# R40 register map
Vendor: Allwinner; Series: R40; File version: 0.1
CPU: CA7 0, little endian, MPU, FPU, double-precision FPU, 0 interrupt priority bits
Registers are 32-bit, read-write, reset 0x0 unless marked. A register's access mark holds for its fields unless they carry their own. Offsets are from the block's base; [hi:lo] are bit positions; lines under a group give offsets from that group; {n}, {i} and the like mark numbered series; 'fields as' and 'values as' point back to an identical list.

## GMAC
Base 0x01C50000
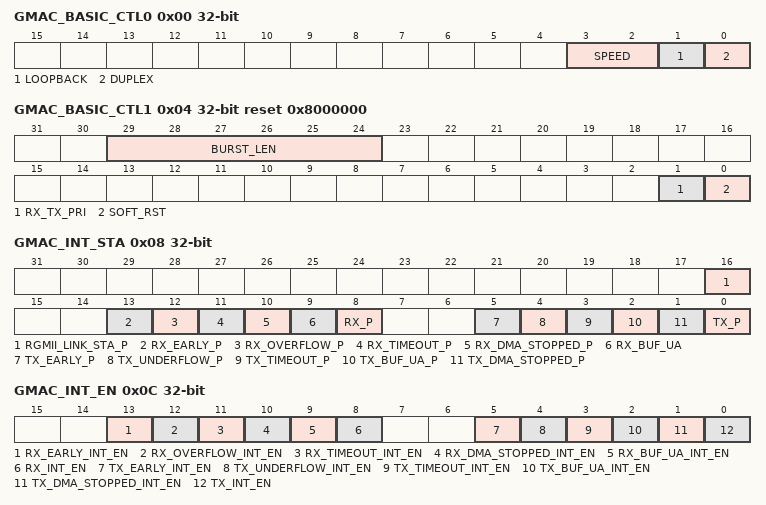
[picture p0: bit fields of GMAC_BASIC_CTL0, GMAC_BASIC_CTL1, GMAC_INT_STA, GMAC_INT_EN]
0x00 GMAC_BASIC_CTL0 — GMAC Basic Control Register0
  [3:2] SPEED — 00: 1000Mbps 01: Reserved 10: 10Mbps 11: 100Mbps
    0=_1000Mbps; 2=_10Mbps; 3=_100Mbps
  [1] LOOPBACK — 0: Disable 1: Enable
    0=Disable; 1=Enable
  [0] DUPLEX — 0: Half-duplex 1: Full-duplex
    0=half_duplex; 1=full_duplex
0x04 GMAC_BASIC_CTL1 reset 0x8000000 — GMAC Basic Control Register1
  [29:24] BURST_LEN — The burst length of RX and TX DMA transfer.
  [1] RX_TX_PRI — RX TX DMA priority 0: same priority 1: RX priority over TX
    0=same priority; 1=RX (RX priority over TX)
  [0] SOFT_RST — Soft Reset all Registers and Logic 0: No valid 1: Reset Note: All clock inputs must be valid before soft rest. This bit is cleared internally when the reset operation is completed fully. Before write any register, this bit should read a 0.
    0=No_valid; 1=Reset Note: All clock inputs must be valid before soft rest. This bit is cleared internally when the reset operation is completed fully. Before write any register, this bit should read a 0.
0x08 GMAC_INT_STA — GMAC Interrupt Status Register
  [16] RGMII_LINK_STA_P write-1-clears — RMII Link Status Changed Interrupt Pending 0: No Pending 1: Pending Note: Write `1` to clear
    0=No_Pending; 1=Pending Note: Write `1` to clear
  [13] RX_EARLY_P write-1-clears — RX DMA Filled First data Buffer of the Receive Frame Interrupt Pending 0: No Pending 1: Pending Note: Write `1` to clear
    0=No_Pending; 1=Pending Note: Write `1` to clear
  [12] RX_OVERFLOW_P write-1-clears — RX FIFO Overflow Error Interrupt Pending 0: No Pending 1: Pending Note: Write `1` to clear
    0=No_Pending; 1=Pending Note: Write `1` to clear
  [11] RX_TIMEOUT_P write-1-clears — RX Timeout Interrupt Pending 0: No Pending 1: Pending Note: Write `1` to clear .When this bit asserted, the length of receive frame is greater than 2048 bytes(10240 when JUMBO_FRM_EN is set)
    0=No_Pending; 1=Pending Note: Write `1` to clear .When this bit asserted, the length of receive frame is greater than 2048 bytes(10240 when JUMBO_FRM_EN is set)
  [10] RX_DMA_STOPPED_P write-1-clears — When this bit asserted, the RX DMA FSM is stopped.
  [9] RX_BUF_UA write-1-clears — _P RX Buffer UA Interrupt Pending 0: No Pending 1: Pending Note: Write `1` to clear .When this asserted, the RX DMA can`t acquire next RX descriptor and RX DMA FSM is suspended. The ownership of next RX descriptor should be changed to RX DMA. The RX DMA FSM will resume when write to DMA_RX_START bit or next receive frame is coming.
    0=No_Pending; 1=Pending Note: Write `1` to clear .When this asserted, the RX DMA can`t acquire next RX descriptor and RX DMA FSM is suspended. The ownership of next RX descriptor should be changed to RX DMA. The RX DMA FSM will resume when write to DMA_RX_START bit or next receive frame is coming.
  [8] RX_P write-1-clears — Frame RX Completed Interrupt Pending 0: No Pending 1: Pending Note: Write `1` to clear. When this bit is asserted, a frame reception is completed. The RX DMA FSM remains in the running state.
    0=No_Pending; 1=Pending Note: Write `1` to clear. When this bit is asserted, a frame reception is completed. The RX DMA FSM remains in the running state.
  [5] TX_EARLY_P write-1-clears — Frame is transmitted to FIFO totally Interrupt Pending 0: No Pending 1: Pending Note: Write `1` to clear.
    0=No_Pending; 1=Pending Note: Write `1` to clear
  [4] TX_UNDERFLOW_P write-1-clears — TX FIFO Underflow Interrupt Pending 0: No Pending 1: Pending Note: Write `1` to clear
    0=No_Pending; 1=Pending Note: Write `1` to clear
  [3] TX_TIMEOUT_P write-1-clears — Transmitter Timeout Interrupt Pending 0: No Pending 1: Pending Note: Write `1` to clear
    0=No_Pending; 1=Pending Note: Write `1` to clear
  [2] TX_BUF_UA_P write-1-clears — TX Buffer UA Interrupt Pending 0: No Pending 1: Pending When this asserted, the TX DMA can not acquire next TX descriptor and TX DMA FSM is suspended. The ownership of next TX descriptor should be changed to TX DMA. The TX DMA FSM will resume when write to DMA_TX_START bit.
    0=No_Pending; 1=Pending When this asserted, the TX DMA can not acquire next TX descriptor and TX DMA FSM is suspended. The ownership of next TX descriptor should be changed to TX DMA. The TX DMA FSM will resume when write to DMA_TX_START bit.
  [1] TX_DMA_STOPPED_P write-1-clears — Transmission DMA Stopped Interrupt Pending 0: No Pending 1: Pending Note: Write `1` to clear
    0=No_Pending; 1=Pending Note: Write `1` to clear
  [0] TX_P write-1-clears — Frame Transmission Interrupt Pending 0: No Pending 1: Pending Note: Write `1` to clear
    0=No_Pending; 1=Pending Note: Write `1` to clear
0x0C GMAC_INT_EN — GMAC Interrupt Enable Register
  [all] fields
    0=Disable; 1=Enable
  [13] RX_EARLY_INT_EN — Early Receive Interrupt 0: Disable 1: Enable
  [12] RX_OVERFLOW_INT_EN — Receive Overflow Interrupt 0: Disable 1: Enable
  [11] RX_TIMEOUT_INT_EN — Receive Timeout Interrupt 0: Disable 1: Enable
  [10] RX_DMA_STOPPED_INT_EN — Receive DMA FSM Stopped Interrupt 0: Disable 1: Enable
  [9] RX_BUF_UA_INT_EN — Receive Buffer Unavailable Interrupt 0: Disable 1: Enable
  [8] RX_INT_EN — Receive interrupt 0: Disable 1: Enable
  [5] TX_EARLY_INT_EN — Early Transmit Interrupt 0: Disable 1: Enable
  [4] TX_UNDERFLOW_INT_EN — Transmit Underflow Interrupt 0: Disable 1: Enable
  [3] TX_TIMEOUT_INT_EN — Transmit Timeout Interrupt 0: Disable 1: Enable
  [2] TX_BUF_UA_INT_EN — Transmit Buffer Available Interrupt 0: Disable 1: Enable
  [1] TX_DMA_STOPPED_INT_EN — Transmit DMA FSM Stopped Interrupt 0: Disable 1: Enable
  [0] TX_INT_EN — Transmit interrupt 0: Disable 1: Enable
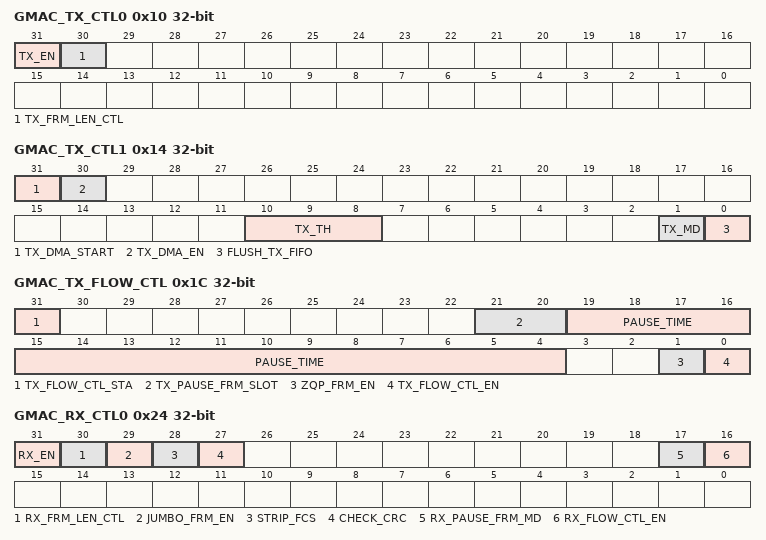
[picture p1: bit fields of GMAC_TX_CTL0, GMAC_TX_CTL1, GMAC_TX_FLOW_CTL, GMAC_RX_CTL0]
0x10 GMAC_TX_CTL0 — GMAC Transmit Control Register0
  [31] TX_EN — Enable transmitter. 0: Disable 1: Enable Note: When disable, transmit will continue until current transmit finish.
    0=Disable; 1=Enable Note: When disable, transmit will continue until current transmit finish
  [30] TX_FRM_LEN_CTL — Frame Transmit Length Control 0: Up to 2,048 bytes (JUMBO_FRM_EN==0) Up to 10,240 bytes (JUMBO_FRM_EN==1) 1: Up to 16,384 bytes Note: any bytes after that is cut off
    0=Up_to_2_comma_048 (Up to 2,048 bytes (JUMBO_FRM_EN==0) Up to 10,240 bytes (JUMBO_FRM_EN==1)); 1=Up_to_16_comma_384 (Up to 16,384 bytes Note: any bytes after that is cut off)
0x14 GMAC_TX_CTL1 — GMAC Transmit Control Register1
  [31] TX_DMA_START — Transmit DMA FSM Start 0: No valid 1: Start Note: This cleared internally and always read a 0
    0=No_valid; 1=Start Note: This cleared internally and always read a 0
  [30] TX_DMA_EN — 0: Stop TX DMA after the completion of current frame transmission. 1: Start and run TX DMA.
    0=Stop TX DMA after the completion of current frame transmission; 1=Start and run TX DMA
  [10:8] TX_TH — The threshold value of TX DMA FIFO. When TX_MD is 0, transmission starts when the size of frame in TX DMA FIFO is greater than the threshold. In addition, full frames with a length less than the threshold are transferred automatically. 000: 64 001: 128 010: 192 011: 256 Others: Reserved
    0=_64; 1=_128; 2=_192; 3=_256
  [1] TX_MD — Transmission Mode 0: TX start after TX DMA FIFO bytes is greater than TX_TH 1: TX start after TX DMA FIFO located a full frame
    0=TX start after TX DMA FIFO bytes is greater than TX_TH; 1=TX start after TX DMA FIFO located a full frame
  [0] FLUSH_TX_FIFO — Flush the data in the TX FIFO. 0: Enable 1: Disable
    0=Enable; 1=Disable
0x1C GMAC_TX_FLOW_CTL — GMAC Transmit Flow Control Register
  [31] TX_FLOW_CTL_STA — This bit indicates a pause frame transmission is in progress. When the configuration of flow control is ready, set this bit to transmit a pause frame in full-duplex mode or activate the backpressure function. After completion of transmission, this bit will be cleared automatically. Before write register TX_FLOW_CTRL, this bit must be read as 0.
  [21:20] TX_PAUSE_FRM_SLOT — The threshold of the pause timer at which the input flow control signal is checked for automatic retransmission of pause frame. The threshold values should be always less than the PAUSE_TIME
  [19:4] PAUSE_TIME — The pause time field in the transmitted control frame.
  [1] ZQP_FRM_EN — 0: Disable 1: Enable When set, enable the functionality to generate Zero-Quanta Pause control frame.
    0=Disable; 1=Enable When set, enable the functionality to generate Zero-Quanta Pause control frame
  [0] TX_FLOW_CTL_EN — TX Flow Control Enable 0: Disable 1: Enable When set, enable flow control operation to transmit pause frames in full-duplex mode, or enable the back-pressure operation in half-duplex mode.
    0=Disable; 1=Enable When set, enable flow control operation to transmit pause frames in full-duplex mode, or enable the back-pressure operation in half-duplex mode
0x20 GMAC_TX_DMA_LIST
  [31:0] TX_DESC_LIST — The base address of transmit descriptor list. It must be 32-bit aligned.
0x24 GMAC_RX_CTL0 — GMAC Receive Control Register0
  [31] RX_EN — Enable receiver 0: Disable receiver after current reception 1: Enable
    0=Disable receiver after current reception; 1=Enable
  [30] RX_FRM_LEN_CTL — Frame Receive Length Control 0: Up to 2,048 bytes (JUMBO_FRM_EN==0) Up to 10,240 bytes (JUMBO_FRM_EN==1) 1: Up to 16,384 bytes Note: any bytes after that is cut off
    values as GMAC_TX_CTL0.TX_FRM_LEN_CTL
  [29] JUMBO_FRM_EN — Jumbo Frame Enable 0: Disable 1: Enable Jumbo frames of 9,018 bytes without reporting a giant
    0=Disable; 1=Enable Jumbo frames of 9,018 bytes without reporting a giant
  [28] STRIP_FCS — When set, strip the Pad/FCS field on received frames only when the length`s field value is less than or equal to 1,500 bytes.
  [27] CHECK_CRC — Check CRC anable 0: Disable 1: Calculate CRC and check the IPv4 Header Checksum.
    0=Disable; 1=Calculate CRC and check the IPv4 Header Checksum
  [17] RX_PAUSE_FRM_MD — 0: Only detect multicast pause frame specified in the 802.3x standard. 1: In addition to detect multicast pause frame specified in the 802.3x standard, also detect unicast pause frame with address specified in MAC Address 0 High Register and MAC address 0 Low Register.
    0=Only detect multicast pause frame specified in the 802.3x standard; 1=In (In addition to detect multicast pause frame specified in the 802.3x standard, also detect unicast pause frame with address specified in MAC Address 0 High Register and MAC address 0 Low Register.)
  [16] RX_FLOW_CTL_EN — When set, enable the functionality that decode the received pause frame and disable its transmitter for a specified time by pause frame.
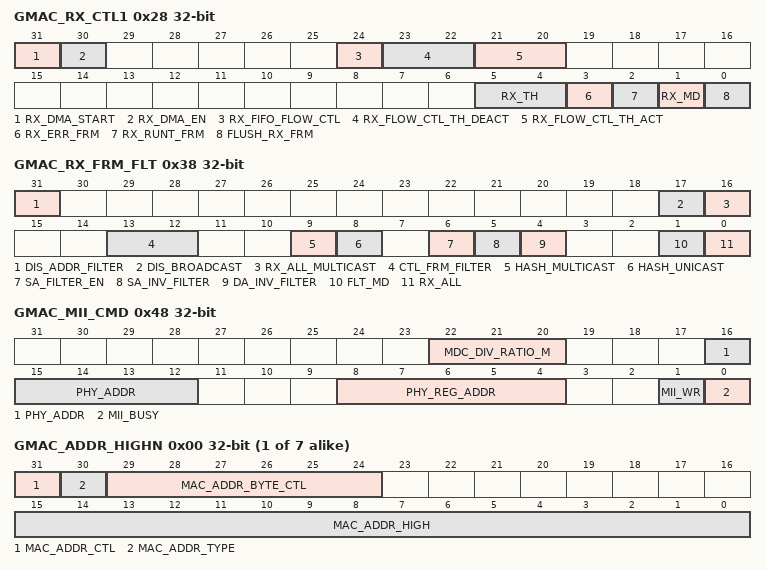
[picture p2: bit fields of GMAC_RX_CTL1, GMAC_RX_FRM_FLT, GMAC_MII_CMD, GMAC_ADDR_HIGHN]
0x28 GMAC_RX_CTL1 — GMAC Receive Control Register1
  [31] RX_DMA_START — When set, the RX DMA will go no to work. It is cleared internally and always read a 0.
  [30] RX_DMA_EN — Receive DMA Enable 0: Stop RX DMA after finish receiving current frame 1: Start and run RX DMA
    0=Stop RX DMA after finish receiving current frame; 1=Start and run RX DMA
  [24] RX_FIFO_FLOW_CTL — Receive FIFO Flow Control Enable 0: Disable 1: Enable,base on RX_FLOW_CTL_TH_DEACT and RX_FLOW_CTL_TH_ACT
    0=Disable; 1=Enable_comma_base (Enable,base on RX_FLOW_CTL_TH_DEACT and RX_FLOW_CTL_TH_ACT)
  [23:22] RX_FLOW_CTL_TH_DEACT — Threshold for Deactivating Flow Control 00: Full minus 1 KB 01: Full minus 2 KB 10: Full minus 3 KB 11: Full minus 4 KB Note: Valid in both half-duplex mode and full-duplex mode.
    0=Full minus 1 KB; 1=Full minus 2 KB; 2=Full minus 3 KB; 3=Full minus 4 KB Note: Valid in both half-duplex mode and full-duplex mode
  [21:20] RX_FLOW_CTL_TH_ACT — Threshold for Activating Flow Control 00: Full minus 1 KB 01: Full minus 2 KB 10: Full minus 3 KB 11: Full minus 4 KB Note: Valid in both half-duplex mode and full-duplex mode.
    values as RX_FLOW_CTL_TH_DEACT
  [5:4] RX_TH — Threshold for RX DMA FIFO Start 00: 64 01: 32 10: 96 11: 128 Note: Only valid when RX_MD == 0, full frames with a length less than the threshold are transferred automatically.
    0=_64; 1=_32; 2=_96; 3=128 Note: Only valid when RX_MD == 0, full frames with a length less than the threshold are transferred automatically
  [3] RX_ERR_FRM — 0: RX DMA drops frames with error 1: RX DMA forwards frames with error
    0=RX DMA drops frames with error; 1=RX DMA forwards frames with error
  [2] RX_RUNT_FRM — When set, forward undersized frames with no error and length less than 64bytes
  [1] RX_MD — Receive Mode 0: RX start read after RX DMA FIFO bytes is greater than RX_TH 1: RX start read after RX DMA FIFO located a full frame
    0=RX start read after RX DMA FIFO bytes is greater than RX_TH; 1=RX start read after RX DMA FIFO located a full frame
  [0] FLUSH_RX_FRM — Flush Receive Frames 0: Enable when receive descriptors/buffers is unavailable 1: Disable
    0=Enable when receive descriptors/buffers is unavailable; 1=Disable
0x34 GMAC_RX_DMA_LIST
  [31:0] RX_DESC_LIST — The base address of receive descriptor list. It must be 32-bit aligned.
0x38 GMAC_RX_FRM_FLT — GMAC Receive Frame Filter Register
  [31] DIS_ADDR_FILTER — Disable Address Filter 0: Enable 1: Disable
    0=Enable; 1=Disable
  [17] DIS_BROADCAST — Disable Receive Broadcast frames 0: Receive 1: Drop
    0=Receive; 1=Drop
  [16] RX_ALL_MULTICAST — Receive All Multicast frames Filter 0: Filter according to HASH_MULTICAST 1: Receive All
    0=Filter according to HASH_MULTICAST; 1=Receive All
  [13:12] CTL_FRM_FILTER — Receive Control Frames Filter 00: Drop all control frames 01: Drop all control frames 10: Receive all control frames 11: Receive all control frames when pass the address filter
  [9] HASH_MULTICAST — Filter multicast frames Set 0: by comparing the DA field in DA MAC address registers 1: according to the hash table
    0=by (by comparing the DA field in DA MAC address registers); 1=according to the hash table
  [8] HASH_UNICAST — Filter Unicast Frames Set 0: by comparing the DA field in DA MAC address registers 1: according to the hash table
    values as HASH_MULTICAST
  [6] SA_FILTER_EN — Receive SA Filter Enable 0: Receive frames and update the result of SA filter 1: Update the result of SA filter. In addition, if the SA field of received frame does not match the values in SA MAC address registers, drop this frame.
    0=Receive frames and update the result of SA filter; 1=Update the result of SA filter. In addition, if the SA field of received frame does not match the values in SA MAC address registers, drop this frame.
  [5] SA_INV_FILTER — Receive SA Invert Filter Set 0: Pass Frames whose SA field matches SA MAC address registers 1: Pass Frames whose SA field not matches SA MAC address registers
    0=Pass Frames whose SA field matches SA MAC address registers; 1=Pass Frames whose SA field not matches SA MAC address registers
  [4] DA_INV_FILTER — 0: Normal filtering of frames is performed 1: Filter both unicast and multicast frames by comparing DA field in inverse filtering mode
    0=Normal filtering of frames is performed; 1=Filter both unicast and multicast frames by comparing DA field in inverse filtering mode
  [1] FLT_MD — 0: If the HASH_MULTICAST or HASH_UNICAST is set, the frame is passed only when it matches the Hash filter 1: Receive the frame when it pass the address register filter or the hash filter(set by HASH_MULTICAST or HASH_UNICAST)
    0=If (If the HASH_MULTICAST or HASH_UNICAST is set, the frame is passed only when it matches the Hash filter); 1=Receive the frame when it pass the address register filter or the hash filter(set by HASH_MULTICAST or HASH_UNICAST)
  [0] RX_ALL — Receive All Frame Enable 0: Receive the frames that pass the SA/DA address filter 1: Receive all frames and update the result of address filter(pass or fail) in the receive status word
    0=Receive the frames that pass the SA/DA address filter; 1=Receive all frames and update the result of address filter(pass or fail) in the receive status word
0x40 GMAC_RX_HASH0 — GMAC Hash Table Register0
  [31:0] HASH_TAB0 — The upper 32 bits of Hash table for receive frame filter.
0x44 GMAC_RX_HASH1 — GMAC Hash Table Register1
  [31:0] HASH_TAB1 — The lower 32 bits of Hash table for receive frame filter.
0x48 GMAC_MII_CMD — GMAC Management Interface Command Register
  [22:20] MDC_DIV_RATIO_M — MDC Clock Divide Ratio 000: 16 001: 32 010: 64 011: 128 Others: Reserved Note: MDC Clock is divided from AHB clock
    0=_16; 1=_32; 2=_64; 3=128 Others: Reserved Note: MDC Clock is divided from AHB clock
  [16:12] PHY_ADDR — PHY Address
  [8:4] PHY_REG_ADDR — PHY Register Address
  [1] MII_WR — MII Write and Read 0: Read 1: Write
    0=Read; 1=Write
  [0] MII_BUSY — 0: Write no valid, read 0 indicate finish in read or write operation 1: Write start read or write operation, read 1 indicate busy.
    0=Write no valid, read 0 indicate finish in read or write operation; 1=Write start read or write operation, read 1 indicate busy
0x4C GMAC_MII_DATA — GMAC Management Interface Data Register
  [15:0] MII_DATA — Written to or read from the register in the selected PHY.
0x50 GMAC_ADDR_HIGH0 reset 0xFFFF — GMAC MAC Address High Register0
  [15:0] MAC_ADDR_HIGH0 — The upper 16bits of the 1st MAC address.
0x54 GMAC_ADDR_LOW0 reset 0xFFFFFFFF — GMAC MAC Address High Register0
  [31:0] MAC_ADDR_LOW0 — The lower 32bits of 1st MAC address.
{0x50+8i} _N_{i} (i=1..7) group
  0x00 GMAC_ADDR_HIGHN
    [31] MAC_ADDR_CTL — MAC Address is valid 0: Not valid 1: Valid
      0=Not_valid; 1=Valid
    [30] MAC_ADDR_TYPE — MAC Address Type 0: Used to compare with the destination address of the received frame 1: Used to compare with the source address of the received frame
      0=Used to compare with the destination address of the received frame; 1=Used to compare with the source address of the received frame
    [29:24] MAC_ADDR_BYTE_CTL — MAC address byte control mask. The lower bit of mask controls the lower byte in MAC address. When the bit of mask is 1, do not compare the corresponding byte.
    [15:0] MAC_ADDR_HIGH — The upper 16bits of the MAC address.
  0x04 GMAC_ADDR_LOWN
    [31:0] MAC_ADDR_LOWN — The lower 32bits of MAC address N (N: 1~7).
0xB0 GMAC_TX_DMA_STA — GMAC Transmit DMA Status Register
  [2:0] TX_DMA_STA ro — The state of Transmit DMA FSM. 000: STOP, When reset or disable TX DMA 001: RUN_FETCH_DESC, Fetching TX DMA descriptor 010: RUN_WAIT_STA, Waiting for the status of TX frame 011: RUN_TRANS_DATA, Passing frame from host memory to TX DMA FIFO 100: Reserved 101: Reserved 110: SUSPEND, TX descriptor unavailable or TX DMA FIFO underflow 111: RUN_CLOSE_DESC, Closing TX descriptor.
    0=STOP (STOP, When reset or disable TX DMA); 1=RUN_FETCH_DESC (RUN_FETCH_DESC, Fetching TX DMA descriptor); 2=RUN_WAIT_STA (RUN_WAIT_STA, Waiting for the status of TX frame); 3=RUN_TRANS_DATA (RUN_TRANS_DATA, Passing frame from host memory to TX DMA FIFO); 6=SUSPEND (SUSPEND, TX descriptor unavailable or TX DMA FIFO underflow); 7=RUN_CLOSE_DESC (RUN_CLOSE_DESC, Closing TX descriptor.)
0xB4 GMAC_TX_DMA_CUR_DESC
  [31:0] CURRENT_TRANSMIT ro — The address of current transmit descriptor.
0xB8 GMAC_TX_DMA_CUR_BUF
  [31:0] CURRENT_TRANSMIT ro — The address of current transmit DMA buffer
0xC0 GMAC_RX_DMA_STA — GMAC Receive DMA Status Register
  [2:0] RX_DMA_STA ro — The state of RX DMA FSM. 000: STOP, When reset or disable RX DMA 001: RUN_FETCH_DESC, Fetching RX DMA descriptor 010: Reserved 011: RUN_WAIT_FRM, Waiting for frame 100: SUSPEND, RX descriptor unavailable 101: RUN_CLOSE_DESC, Closing RX descriptor 110: Reserved 111: RUN_TRANS_DATA, Passing frame from host memory to RX DMA FIFO
    0=STOP (STOP, When reset or disable RX DMA); 1=RUN_FETCH_DESC (RUN_FETCH_DESC, Fetching RX DMA descriptor); 3=RUN_WAIT_FRM (RUN_WAIT_FRM, Waiting for frame); 4=SUSPEND (SUSPEND, RX descriptor unavailable); 5=RUN_CLOSE_DESC (RUN_CLOSE_DESC, Closing RX descriptor); 7=RUN_TRANS_DATA (RUN_TRANS_DATA, Passing frame from host memory to RX DMA FIFO)
0xC4 GMAC_RX_DMA_CUR_DESC
  [31:0] CURRENT_RECEIVE ro — The address of current receive descriptor
0xC8 GMAC_RX_DMA_CUR_BUF
  [31:0] CURRENT_RECEIVE ro — The address of current receive DMA buffer
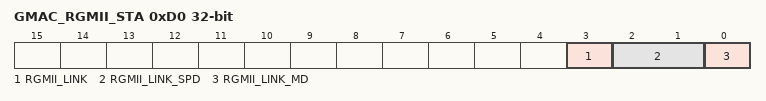
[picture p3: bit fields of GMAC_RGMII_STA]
0xD0 GMAC_RGMII_STA — GMAC RGMII Status Register
  [3] RGMII_LINK ro — The link status of RGMII interface 0: Down 1: Up
    0=Down; 1=Up
  [2:1] RGMII_LINK_SPD ro — The link speed of RGMII interface 00: 2.5 MHz 01: 25 MHz 10: 125 MHz 11: Reserved
    0=_2_point_5 (2.5 MHz); 1=25 MHz; 2=125 MHz
  [0] RGMII_LINK_MD ro — The link Mode of RGMII interface 0: Half-Duplex 1: Full-Duplex
    0=half_Duplex; 1=full_Duplex
